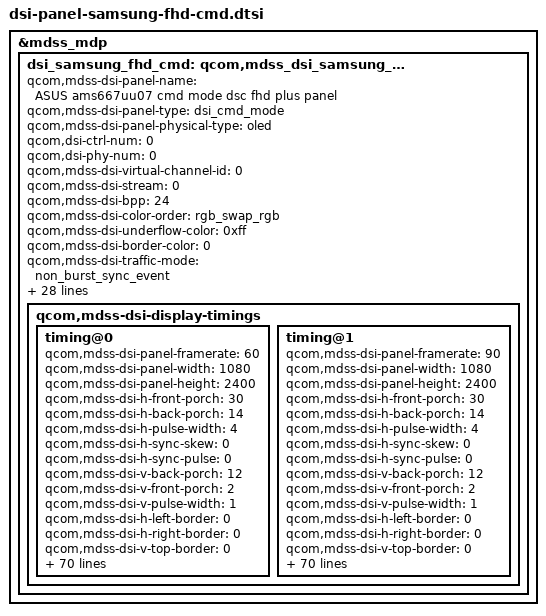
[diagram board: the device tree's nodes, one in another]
&mdss_mdp {
	dsi_samsung_fhd_cmd: qcom,mdss_dsi_samsung_fhd_cmd {
		qcom,mdss-dsi-panel-name = "ASUS ams667uu07 cmd mode dsc fhd plus panel";
		qcom,mdss-dsi-panel-type = "dsi_cmd_mode";
		qcom,mdss-dsi-panel-physical-type = "oled";
		qcom,dsi-ctrl-num = <0>;
		qcom,dsi-phy-num = <0>;
		qcom,mdss-dsi-virtual-channel-id = <0>;
		qcom,mdss-dsi-stream = <0>;
		qcom,mdss-dsi-bpp = <24>;
		qcom,mdss-dsi-color-order = "rgb_swap_rgb";
		qcom,mdss-dsi-underflow-color = <0xff>;
		qcom,mdss-dsi-border-color = <0>;
		qcom,mdss-dsi-traffic-mode = "non_burst_sync_event";
		qcom,mdss-dsi-lane-map = "lane_map_0123";
		qcom,mdss-dsi-bllp-eof-power-mode;
		qcom,mdss-dsi-bllp-power-mode;
		qcom,mdss-dsi-lane-0-state;
		qcom,mdss-dsi-lane-1-state;
		qcom,mdss-dsi-lane-2-state;
		qcom,mdss-dsi-lane-3-state;
		qcom,mdss-dsi-dma-trigger = "trigger_sw";
		qcom,mdss-dsi-mdp-trigger = "none";
		qcom,mdss-dsi-reset-sequence = <0 1>,<0 1>, <1 1>;
		qcom,mdss-dsi-te-pin-select = <1>;
		qcom,mdss-dsi-wr-mem-start = <0x2c>;
		qcom,mdss-dsi-wr-mem-continue = <0x3c>;
		qcom,mdss-dsi-te-dcs-command = <1>;
		qcom,mdss-dsi-te-check-enable;
		qcom,mdss-dsi-te-using-te-pin;
		qcom,mdss-pan-physical-width-dimension = <70>;
		qcom,mdss-pan-physical-height-dimension = <155>;
		qcom,mdss-dsi-panel-hdr-enabled;
		qcom,mdss-dsi-panel-hdr-color-primaries = <15635 16450 34000
			16000 13250 34500 7500 3000>;
		qcom,mdss-dsi-panel-peak-brightness = <5000000>;
		qcom,mdss-dsi-panel-blackness-level = <5>;

		qcom,mdss-dsi-panel-vendor-id = "AMS667UU07";
		qcom,mdss-dsi-bl-inverted-dbv;
		qcom,dynamic-mode-switch-enabled;
		qcom,dynamic-mode-switch-type = "dynamic-resolution-switch-immediate";

		qcom,mdss-dsi-display-timings {
			timing@0{
				qcom,mdss-dsi-panel-framerate = <60>;
				qcom,mdss-dsi-panel-width = <1080>;
				qcom,mdss-dsi-panel-height = <2400>;
				qcom,mdss-dsi-h-front-porch = <30>;
				qcom,mdss-dsi-h-back-porch = <14>;
				qcom,mdss-dsi-h-pulse-width = <4>;
				qcom,mdss-dsi-h-sync-skew = <0>;
				qcom,mdss-dsi-h-sync-pulse = <0>;
				qcom,mdss-dsi-v-back-porch = <12>;
				qcom,mdss-dsi-v-front-porch = <2>;
				qcom,mdss-dsi-v-pulse-width = <1>;
				qcom,mdss-dsi-h-left-border = <0>;
				qcom,mdss-dsi-h-right-border = <0>;
				qcom,mdss-dsi-v-top-border = <0>;
				qcom,mdss-dsi-v-bottom-border = <0>;
				qcom,mdss-dsi-panel-jitter = <0x05 0xa>;
				qcom,mdss-dsi-panel-clockrate = <668000000>;

				qcom,mdss-dsi-on-command = [
					05 01 00 00 10 00 02 11 00
					15 01 00 00 00 00 02 9D 01
					39 01 00 00 00 00 59 9E 11 00 00 89 30 80 09 60 04 38 00 30 02 1C 02 1C 02 00 02 52 00 20 04 23 00 07 00 0F 02 8E 02 1F 18 00 10 F0 03 0C 20 00 06 0B 0B 33 0E 1C 2A 38 46 54 62 69 70 77 79 7B 7D 7E 01 02 01 00 09 40 09 BE 19 FC 19 FA 19 F8 1A 38 1A 78 1A B6 2A B6 2A F4 2A F4 4B 34 63 74
					39 01 00 00 00 00 03 F0 5A 5A
					15 01 00 00 00 00 02 B0 03
					39 01 00 00 00 00 05 F5 18 64 10 67
					39 01 00 00 00 00 03 F0 A5 A5
					15 01 00 00 00 00 02 35 00
					39 01 00 00 00 00 05 2A 00 00 04 37
					39 01 00 00 00 00 05 2B 00 00 09 5F
					39 01 00 00 00 00 03 F0 5A 5A
					15 01 00 00 00 00 02 B0 1A
					15 01 00 00 00 00 02 F9 20
					39 01 00 00 00 00 04 E5 13 E8 FC
					39 01 00 00 00 00 05 ED 97 00 0F 90
					15 01 00 00 00 00 02 B0 0A
					15 01 00 00 00 00 02 F2 C0
					39 01 00 00 6E 00 03 F0 A5 A5
					15 01 00 00 00 00 02 53 28
					39 01 00 00 00 00 03 51 00 00
					15 01 00 00 00 00 02 55 00
					05 01 00 00 00 00 02 29 00
					15 01 00 00 00 00 02 60 00
				];

				qcom,mdss-dsi-off-command = [
					05 01 00 00 32 00 02 28 00
					05 01 00 00 78 00 02 10 00
				];

				qcom,mdss-dsi-timing-switch-command = [
					15 01 00 00 00 00 02 60 00
				];

				qcom,mdss-dsi-hbm-on-command = [
					15 01 00 00 00 00 02 53 E0
				];

				qcom,mdss-dsi-hbm-off-command = [
					15 01 00 00 00 00 02 53 28
				];

				qcom,mdss-dsi-fod-hbm-on-command = [
					39 01 00 00 00 00 03 51 03 FF
					15 01 00 00 00 00 02 53 E0
				];

				qcom,mdss-dsi-fod-hbm-off-command = [
					15 01 00 00 00 00 02 53 20
				];

				qcom,mdss-dsi-lp1-command = [
					05 01 00 00 00 00 02 28 00
				];

				qcom,mdss-dsi-nolp-command = [
					15 01 00 00 00 00 02 60 00
					15 01 00 00 11 00 02 53 28
					05 01 00 00 00 00 02 29 00
				];

				qcom,mdss-dsi-aod-high-command = [
					15 01 00 00 00 00 02 60 00
					15 01 00 00 22 00 02 53 22
					05 01 00 00 00 00 02 29 00
				];

				qcom,mdss-dsi-aod-low-command = [
					15 01 00 00 00 00 02 60 00
					15 01 00 00 22 00 02 53 23
					05 01 00 00 00 00 02 29 00
				];

				qcom,mdss-dsi-aod-other-command = [
					05 01 00 00 00 00 02 29 00
				];

				qcom,mdss-dsi-dimming-speed-1frame-command = [
					39 01 00 00 00 00 03 F0 5A 5A
					15 01 00 00 00 00 02 B0 06
					15 01 00 00 00 00 02 B7 01
					39 01 00 00 00 00 03 F0 A5 A5
				];

				qcom,mdss-dsi-dimming-speed-20frame-command = [
					39 01 00 00 00 00 03 F0 5A 5A
					15 01 00 00 00 00 02 B0 06
					15 01 00 00 00 00 02 B7 14
					39 01 00 00 00 00 03 F0 A5 A5
				];

				qcom,mdss-dsi-dimming-smooth-command = [
					15 01 00 00 00 00 02 53 28
				];

				qcom,mdss-dsi-aod-off-command = [
					05 01 00 00 10 00 02 28 00
				];

				qcom,mdss-dsi-on-command-state = "dsi_lp_mode";
				qcom,mdss-dsi-off-command-state = "dsi_hs_mode";
				qcom,mdss-dsi-timing-switch-command-state = "dsi_hs_mode";
				qcom,mdss-dsi-hbm-on-command-state = "dsi_hs_mode";
				qcom,mdss-dsi-hbm-off-command-state = "dsi_hs_mode";
				qcom,mdss-dsi-fod-hbm-on-command-state = "dsi_hs_mode";
				qcom,mdss-dsi-fod-hbm-off-command-state = "dsi_hs_mode";
				qcom,mdss-dsi-lp1-command-state = "dsi_hs_mode";
				qcom,mdss-dsi-nolp-command-state = "dsi_hs_mode";
				qcom,mdss-dsi-aod-high-command-state = "dsi_hs_mode";
				qcom,mdss-dsi-aod-low-command-state = "dsi_hs_mode";
				qcom,mdss-dsi-aod-other-command-state = "dsi_hs_mode";
				qcom,mdss-dsi-dimming-speed-1frame-command-state = "dsi_hs_mode";
				qcom,mdss-dsi-dimming-speed-20frame-command-state = "dsi_hs_mode";
				qcom,mdss-dsi-dimming-smooth-command-state = "dsi_hs_mode";
				qcom,mdss-dsi-aod-off-command-state = "dsi_hs_mode";

				/* DSC */
				qcom,compression-mode = "dsc";
				qcom,mdss-dsc-slice-height = <48>;
				qcom,mdss-dsc-slice-width = <540>;
				qcom,mdss-dsc-slice-per-pkt = <2>;
				qcom,mdss-dsc-bit-per-component = <8>;
				qcom,mdss-dsc-bit-per-pixel = <8>;
				qcom,mdss-dsc-block-prediction-enable;
			};

			timing@1{
				qcom,mdss-dsi-panel-framerate = <90>;
				qcom,mdss-dsi-panel-width = <1080>;
				qcom,mdss-dsi-panel-height = <2400>;
				qcom,mdss-dsi-h-front-porch = <30>;
				qcom,mdss-dsi-h-back-porch = <14>;
				qcom,mdss-dsi-h-pulse-width = <4>;
				qcom,mdss-dsi-h-sync-skew = <0>;
				qcom,mdss-dsi-h-sync-pulse = <0>;
				qcom,mdss-dsi-v-back-porch = <12>;
				qcom,mdss-dsi-v-front-porch = <2>;
				qcom,mdss-dsi-v-pulse-width = <1>;
				qcom,mdss-dsi-h-left-border = <0>;
				qcom,mdss-dsi-h-right-border = <0>;
				qcom,mdss-dsi-v-top-border = <0>;
				qcom,mdss-dsi-v-bottom-border = <0>;
				qcom,mdss-dsi-panel-jitter = <0x05 0xa>;
				qcom,mdss-dsi-panel-clockrate = <668000000>;

				qcom,mdss-dsi-on-command = [
					05 01 00 00 10 00 02 11 00
					15 01 00 00 00 00 02 9D 01
					39 01 00 00 00 00 59 9E 11 00 00 89 30 80 09 60 04 38 00 30 02 1C 02 1C 02 00 02 52 00 20 04 23 00 07 00 0F 02 8E 02 1F 18 00 10 F0 03 0C 20 00 06 0B 0B 33 0E 1C 2A 38 46 54 62 69 70 77 79 7B 7D 7E 01 02 01 00 09 40 09 BE 19 FC 19 FA 19 F8 1A 38 1A 78 1A B6 2A B6 2A F4 2A F4 4B 34 63 74
					39 01 00 00 00 00 03 F0 5A 5A
					15 01 00 00 00 00 02 B0 03
					39 01 00 00 00 00 05 F5 18 64 10 67
					39 01 00 00 00 00 03 F0 A5 A5
					15 01 00 00 00 00 02 35 00
					39 01 00 00 00 00 05 2A 00 00 04 37
					39 01 00 00 00 00 05 2B 00 00 09 5F
					39 01 00 00 00 00 03 F0 5A 5A
					15 01 00 00 00 00 02 B0 1A
					15 01 00 00 00 00 02 F9 20
					39 01 00 00 00 00 04 E5 13 E8 FC
					39 01 00 00 00 00 05 ED 97 00 0F 90
					15 01 00 00 00 00 02 B0 0A
					15 01 00 00 00 00 02 F2 C0
					39 01 00 00 6E 00 03 F0 A5 A5
					15 01 00 00 00 00 02 53 28
					39 01 00 00 00 00 03 51 00 00
					15 01 00 00 00 00 02 55 00
					05 01 00 00 00 00 02 29 00
					15 01 00 00 00 00 02 60 10
				];

				qcom,mdss-dsi-off-command = [
					05 01 00 00 32 00 02 28 00
					05 01 00 00 78 00 02 10 00
				];

				qcom,mdss-dsi-timing-switch-command = [
					15 01 00 00 00 00 02 60 10
				];

				qcom,mdss-dsi-hbm-on-command = [
					15 01 00 00 00 00 02 53 E0
				];

				qcom,mdss-dsi-hbm-off-command = [
					15 01 00 00 00 00 02 53 20
				];

				qcom,mdss-dsi-fod-hbm-on-command = [
					39 01 00 00 00 00 03 51 03 FF
					15 01 00 00 00 00 02 53 E0
				];

				qcom,mdss-dsi-fod-hbm-off-command = [
					15 01 00 00 00 00 02 53 20
				];

				qcom,mdss-dsi-lp1-command = [
					05 01 00 00 00 00 02 28 00
				];

				qcom,mdss-dsi-nolp-command = [
					15 01 00 00 00 00 02 60 10
					15 01 00 00 11 00 02 53 28
					05 01 00 00 00 00 02 29 00
				];

				qcom,mdss-dsi-aod-high-command = [
					15 01 00 00 00 00 02 60 00
					15 01 00 00 22 00 02 53 22
					05 01 00 00 00 00 02 29 00
				];

				qcom,mdss-dsi-aod-low-command = [
					15 01 00 00 00 00 02 60 00
					15 01 00 00 22 00 02 53 23
					05 01 00 00 00 00 02 29 00
				];

				qcom,mdss-dsi-aod-other-command = [
					05 01 00 00 00 00 02 29 00
				];

				qcom,mdss-dsi-dimming-speed-1frame-command = [
					39 01 00 00 00 00 03 F0 5A 5A
					15 01 00 00 00 00 02 B0 06
					15 01 00 00 00 00 02 B7 01
					39 01 00 00 00 00 03 F0 A5 A5
				];

				qcom,mdss-dsi-dimming-speed-20frame-command = [
					39 01 00 00 00 00 03 F0 5A 5A
					15 01 00 00 00 00 02 B0 06
					15 01 00 00 00 00 02 B7 14
					39 01 00 00 00 00 03 F0 A5 A5
				];

				qcom,mdss-dsi-dimming-smooth-command = [
					15 01 00 00 00 00 02 53 28
				];

				qcom,mdss-dsi-aod-off-command = [
					05 01 00 00 10 00 02 28 00
				];

				qcom,mdss-dsi-on-command-state = "dsi_lp_mode";
				qcom,mdss-dsi-off-command-state = "dsi_hs_mode";
				qcom,mdss-dsi-timing-switch-command-state = "dsi_hs_mode";
				qcom,mdss-dsi-hbm-on-command-state = "dsi_hs_mode";
				qcom,mdss-dsi-hbm-off-command-state = "dsi_hs_mode";
				qcom,mdss-dsi-fod-hbm-on-command-state = "dsi_hs_mode";
				qcom,mdss-dsi-fod-hbm-off-command-state = "dsi_hs_mode";
				qcom,mdss-dsi-lp1-command-state = "dsi_hs_mode";
				qcom,mdss-dsi-nolp-command-state = "dsi_hs_mode";
				qcom,mdss-dsi-aod-high-command-state = "dsi_hs_mode";
				qcom,mdss-dsi-aod-low-command-state = "dsi_hs_mode";
				qcom,mdss-dsi-aod-other-command-state = "dsi_hs_mode";
				qcom,mdss-dsi-dimming-speed-1frame-command-state = "dsi_hs_mode";
				qcom,mdss-dsi-dimming-speed-20frame-command-state = "dsi_hs_mode";
				qcom,mdss-dsi-dimming-smooth-command-state = "dsi_hs_mode";
				qcom,mdss-dsi-aod-off-command-state = "dsi_hs_mode";

				/* DSC */
				qcom,compression-mode = "dsc";
				qcom,mdss-dsc-slice-height = <48>;
				qcom,mdss-dsc-slice-width = <540>;
				qcom,mdss-dsc-slice-per-pkt = <2>;
				qcom,mdss-dsc-bit-per-component = <8>;
				qcom,mdss-dsc-bit-per-pixel = <8>;
				qcom,mdss-dsc-block-prediction-enable;
			};
		};	
	};
};
